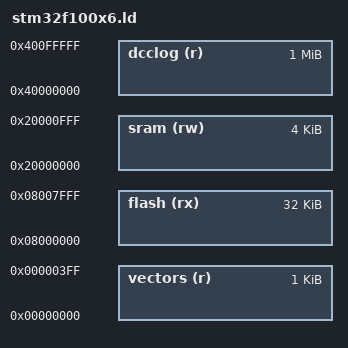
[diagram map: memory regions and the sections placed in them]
/* 
 * stm32f100x6.ld
 *
 * Copyright(C) 2013 Robinson Mittmann. All Rights Reserved.
 * 
 * This file is part of the ThinkOS library.
 *
 * This library is free software; you can redistribute it and/or
 * modify it under the terms of the GNU Lesser General Public
 * License as published by the Free Software Foundation; either
 * version 3.0 of the License, or (at your option) any later version.
 * 
 * This library is distributed in the hope that it will be useful,
 * but WITHOUT ANY WARRANTY; without even the implied warranty of
 * MERCHANTABILITY or FITNESS FOR A PARTICULAR PURPOSE.  See the GNU
 * Lesser General Public License for more details.
 * 
 * You can receive a copy of the GNU Lesser General Public License from 
 * http://www.gnu.org/
 */

/* 
   Medium-density performance line ARM-based 32-bit MCU with 64
   or 128 KB Flash, USB, CAN, 7 timers, 2 ADCs, 9 com. interfaces
*/

OUTPUT_FORMAT ("elf32-littlearm")
ENTRY(_reset)
SEARCH_DIR(.)

MEMORY
{
	vectors(r) : ORIGIN = 0x00000000, LENGTH = 1K
	flash (rx) : ORIGIN = 0x08000000, LENGTH = 32K
	sram (rw) : ORIGIN = 0x20000000, LENGTH = 4K
	dcclog (r) : ORIGIN = 0x40000000, LENGTH = 1024K
}

INCLUDE stm32f100.ld

